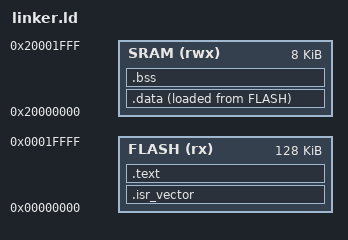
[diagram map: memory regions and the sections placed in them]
ENTRY(Reset_Handler)

MEMORY
{
    FLASH (rx)  : ORIGIN = 0x00000000, LENGTH = 128K
    SRAM  (rwx) : ORIGIN = 0x20000000, LENGTH = 8K
}

_estack = ORIGIN(SRAM) + LENGTH(SRAM);

SECTIONS
{
    .isr_vector :
    {
        . = ALIGN(4);
        KEEP(*(.isr_vector))
        . = ALIGN(4);
    } > FLASH

    .text :
    {
        . = ALIGN(4);
        *(.text*)
        *(.rodata*)
        . = ALIGN(4);
        _etext = .;
    } > FLASH

    /*
     * Initialized data.
     * Stored in FLASH but copied to SRAM by Reset_Handler.
     */
    .data :
    {
        . = ALIGN(4);
        _sdata = .;
        *(.data*)
        . = ALIGN(4);
        _edata = .;
    } > SRAM AT > FLASH

    _sidata = LOADADDR(.data);

    /*
     * Zero-initialized data.
     */
    .bss :
    {
        . = ALIGN(4);
        _sbss = .;
        *(.bss*)
        *(COMMON)
        . = ALIGN(4);
        _ebss = .;
    } > SRAM

    /DISCARD/ :
    {
        *(.note*)
        *(.comment*)
        *(.eh_frame*)
    }
}
